# RZN2H register map
Vendor: Renesas Electronics Corporation; Series: RZN; File version: 1.00.00
CPU: other r0p0, little endian, MPU, no FPU, VTOR, 4 interrupt priority bits, 624 interrupts
Registers are 32-bit, read-write, reset 0x0 unless marked. A register's access mark holds for its fields unless they carry their own. Offsets are from the block's base; [hi:lo] are bit positions; {n}, {i} and the like mark numbered series; 'fields as' and 'values as' point back to an identical list.

## ENCSS — Encoder Interface Subsystem
Base 0x80291000
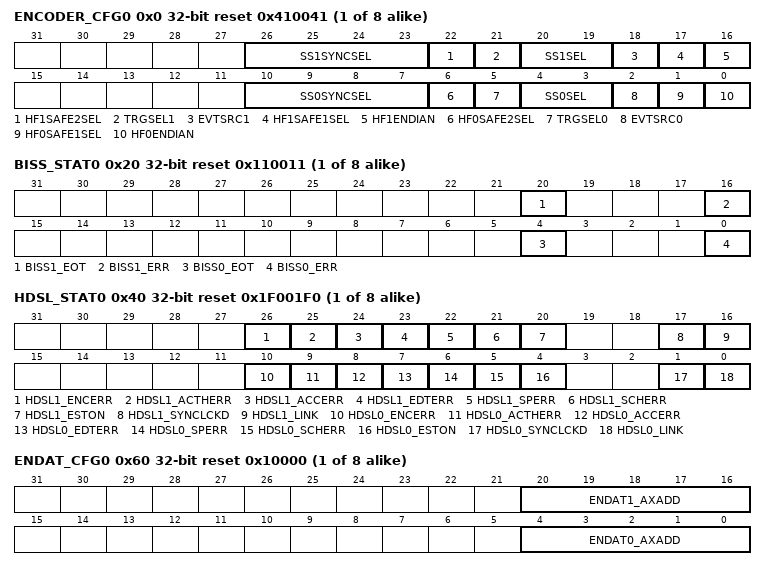
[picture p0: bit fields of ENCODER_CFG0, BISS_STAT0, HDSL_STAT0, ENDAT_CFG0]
{0x0+4i} ENCODER_CFG{i} (i=0..7) reset 0x410041 — Encoder IF Configuration Register {i}
  [26:23] SS1SYNCSEL — Event Source Unit Number Select
  [22] HF1SAFE2SEL — HIPERFACE DSL Unit 2*n+1 Safe 2 Interface Select
    0=Internal bus interface; 1=SPI interface
  [21] TRGSEL1 — EnDat 2.2 Unit 2*n+1 Trigger Output Source Select
    0=Synchronized Trigger out 2*n+1 from ELC; 1=Timer output from EnDat 2.2 Unit 2*n+1
  [20:19] SS1SEL — Encoder Interface Port Select
    0=HIPERFACE DSL; 1=BiSS-C; 2=EnDat 2.2; 3=A-format
  [18] EVTSRC1 — Event Source Select
    0=Trigger out 2*n+1 from ELC; 1=Trigger out from other units of encoder interface subsystem. Used unit is selected by SS0SYNCSEL[3:0] bits. The event source unit and triggered unit should be same protocol.
  [17] HF1SAFE1SEL — HIPERFACE DSL Unit 2*n+1 Safe 1 Interface Select
    0=Internal bus interface; 1=SPI interface
  [16] HF1ENDIAN — HIPERFACE DSL Unit 2*n+1 Endian Mode
    0=Little endian; 1=Big endian
  [10:7] SS0SYNCSEL — Event Source Unit Number Select
  [6] HF0SAFE2SEL — HIPERFACE DSL Unit 2*n Safe 2 Interface Select
    0=Internal bus interface; 1=SPI interface
  [5] TRGSEL0 — EnDat 2.2 Unit 2*n Trigger Output Source Select
    0=Synchronized Trigger out 2*n from ELC; 1=Timer output from EnDat 2.2 Unit 2*n
  [4:3] SS0SEL — Encoder Interface Port Select
    0=HIPERFACE DSL; 1=BiSS-C; 2=EnDat 2.2; 3=A-format
  [2] EVTSRC0 — Event Source Select
    0=Trigger out 2*n from ELC; 1=Trigger out from other units of encoder interface subsystem. Used unit is selected by SS0SYNCSEL[3:0] bits. The event source unit and triggered unit should be same protocol.
  [1] HF0SAFE1SEL — HIPERFACE DSL Unit 2*n Safe 1 Interface Select
    0=Internal bus interface; 1=SPI interface
  [0] HF0ENDIAN — HIPERFACE DSL Unit 2*n Endian Mode
    0=Little endian; 1=Big endian
{0x20+4i} BISS_STAT{i} (i=0..7) ro reset 0x110011 — BiSS-C Status Register {i}
  [20] BISS1_EOT — End-of-Transmission from BiSS-C Unit 2*n+1
    0=Data transmission active; 1=Data transmission inactive
  [16] BISS1_ERR — BiSS-C Unit 2*n+1 Error
    0=External or internal error occurred; 1=No error occurred
  [4] BISS0_EOT — End-of-Transmission from BiSS-C Unit 2*n
    0=Data transmission active; 1=Data transmission inactive
  [0] BISS0_ERR — BiSS-C Unit 2*n Error
    0=External or internal error occurred; 1=No error occurred
{0x40+4i} HDSL_STAT{i} (i=0..7) ro reset 0x1F001F0 — HIPERFACE DSL Status Register {i}
  [26] HDSL1_ENCERR — HIPERFACE-DSL Encoding Error
    0=No error; 1=Error
  [25] HDSL1_ACTHERR — HIPERFACE-DSL Acceleration Threshold Error
    0=No error; 1=Error
  [24] HDSL1_ACCERR — HIPERFACE-DSL Acceleration Error
    0=No error; 1=Error
  [23] HDSL1_EDTERR — HIPERFACE-DSL Estimator Deviation Threshold Error
    0=No error; 1=Error
  [22] HDSL1_SPERR — HIPERFACE-DSL Safe Position Error
    0=No error; 1=Error
  [21] HDSL1_SCHERR — HIPERFACE-DSL Safe Channel Error
    0=No error; 1=Error
  [20] HDSL1_ESTON — HIPERFACE-DSL Estimator ON
    0=Inactive; 1=Active
  [17] HDSL1_SYNCLCKD — HIPERFACE-DSL Sync Locked
    0=Unlock; 1=Locked
  [16] HDSL1_LINK — HIPERFACE-DSL Link
    0=Disconnect; 1=Connect
  [10] HDSL0_ENCERR — HIPERFACE-DSL Encoding Error
    0=No error; 1=Error
  [9] HDSL0_ACTHERR — HIPERFACE-DSL Acceleration Threshold Error
    0=No error; 1=Error
  [8] HDSL0_ACCERR — HIPERFACE-DSL Acceleration Error
    0=No error; 1=Error
  [7] HDSL0_EDTERR — HIPERFACE-DSL Estimator Deviation Threshold Error
    0=No error; 1=Error
  [6] HDSL0_SPERR — HIPERFACE-DSL Safe Position Error
    0=No error; 1=Error
  [5] HDSL0_SCHERR — HIPERFACE-DSL Safe Channel Error
    0=No error; 1=Error
  [4] HDSL0_ESTON — HIPERFACE-DSL Estimator ON
    0=Inactive; 1=Active
  [1] HDSL0_SYNCLCKD — HIPERFACE-DSL Sync Locked
    0=Unlock; 1=Locked
  [0] HDSL0_LINK — HIPERFACE-DSL Link
    0=Disconnect; 1=Connect
{0x60+4i} ENDAT_CFG{i} (i=0..7) reset 0x10000 — EnDat Configuration Register {i}
  [20:16] ENDAT1_AXADD — EnDat Unit 2*n+1 Axis Address
  [4:0] ENDAT0_AXADD — EnDat Unit 2*n Axis Address
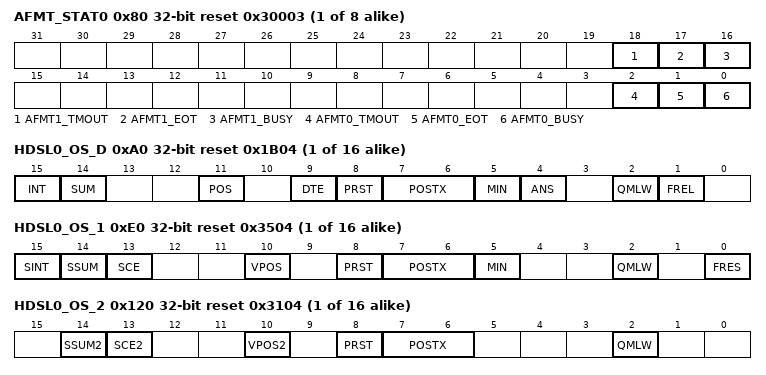
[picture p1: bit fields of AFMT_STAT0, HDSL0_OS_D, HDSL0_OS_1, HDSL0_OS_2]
{0x80+4i} AFMT_STAT{i} (i=0..7) ro reset 0x30003 — A-Format Status Register {i}
  [18] AFMT1_TMOUT — A-format Timeout
    0=No error; 1=Time out error
  [17] AFMT1_EOT — A-format End-of-Frame
    0=Data transfer end (cleared by data read); 1=Idle or in-progress
  [16] AFMT1_BUSY — A-format Busy
    0=Busy; 1=Idle
  [2] AFMT0_TMOUT — A-format Timeout
    0=No error; 1=Time out error
  [1] AFMT0_EOT — A-format End-Of-Frame
    values as AFMT1_EOT
  [0] AFMT0_BUSY — A-format Busy
    0=Busy; 1=Idle
{0xA0+4i} HDSL{i}_OS_D (i=0..15) ro reset 0x1B04 — HIPERFACE_DSL Online Status D Register {i}
  [15] INT — Status of the Interrupt Output
    0=Interrupt output on the low level; 1=Interrupt output on the high level
  [14] SUM — Summary Byte
    0=The last valid value from MIR_SUM was zero; 1=The last valid value from MIR_SUM was not zero. The importance of this flag depends on the particular error source that leads to a set MIR_SUM.
  [11] POS — Estimator Turned On
    0=No fast position error; 1=A source of an error in the fast position was identified or an alignment procedure is currently being carried out. It is probable that the last fast position is invalid. Be aware that the fast position read through drive interface is provided by the estimator.
  [9] DTE — Deviation Threshold Error
    0=Current value of deviation smaller than the specified maximum; 1=Current value of deviation greater than the specified maximum
  [8] PRST — Protocol Reset
    0=HDSLn running; 1=HDSLn has restarted the protocol
  [7:6] POSTX — Position Transmission Status
    0=Position request is transmitted to the DSL encoder; 1=Safe position 1 was received; 2=Fast position was received or position newly updated by estimator; 3=Safe position 2 was received
  [5] MIN — Acknowledgment of Message Initialization
    0=Parameter Channel not functioning; 1=The DSL encoder sends a figure by which the initialization of the Parameter Channel is acknowledged
  [4] ANS — Incorrect Answer Detected
    0=No error detected in the last answer to a long message; 1=The last answer to a long message was damaged
  [2] QMLW — Quality monitoring at Low level
    0=Current value of quality monitoring greater than or equal to 14; 1=Current value of quality monitoring less than 14
  [1] FREL — Channel Status for long message
    0=The channel for the long message is in use; 1=The channel for the long message is free
{0xE0+4i} HDSL{i}_OS_1 (i=0..15) ro reset 0x3504 — HIPERFACE_DSL Online Status 1 Register {i}
  [15] SINT — Status of the Interrupt Output
    values as HDSL0_OS_D.INT
  [14] SSUM — Safe Summary Bit
    0=The last valid value from SAFE_SUM was zero; 1=The last valid value from SAFE_SUM was not zero. The importance of this flag depends on the particular error source that leads to a set SAFE_SUM.
  [13] SCE — CRC Error on the Safe Channel
    0=The last Safe Channel CRC received was correct; 1=The last Safe Channel CRC received was wrong. It is expected that the last safe position 2 transmitted is invalid.
  [10] VPOS — Safe Position Invalid
    0=The last safe position received was correct; 1=An error in the safe position was identified. It is expected that the safe position transmitted from the encoder is invalid.
  [8] PRST — Protocol Reset
    0=HDSL0 running; 1=HDSL0 has restarted the protocol
  [7:6] POSTX — Position Transmission Status
    values as HDSL0_OS_D.POSTX
  [5] MIN — Acknowledgment of Message Initialization
    0=Parameter channel not functioning; 1=The DSL encoder sends a figure by which the initialization of the parameter channel is acknowledged
  [2] QMLW — Quality Monitoring at Low level
    values as HDSL0_OS_D.QMLW
  [0] FRES — Channel Status for the short message
    0=The channel for the short message is in use; 1=The channel for the short message is free
{0x120+4i} HDSL{i}_OS_2 (i=0..15) ro reset 0x3104 — HIPERFACE_DSL Online Status 2 Register {i}
  [14] SSUM2 — Summary Bit Channel 2
    0=Neither TEST2 nor ERR2 is set; 1=One of the indications TEST2 or ERR2 is set. The error reaction to the flag depends on the meaning of the bit.
  [13] SCE2 — Transmission Error Channel 2
    0=The last data received in channel 2 was correct; 1=The last safe channel 2 CRC received was wrong. It is expected that the last safe position 2 transmitted is invalid. Suitable measures must be installed in the user application.
  [10] VPOS2 — Safe Position 2 Invalid
    0=The last safe position received in channel 2 was correct; 1=A source of an error in the safe position in channel 2 was identified. It is probable that the safe position transmitted from Channel 2 is invalid. Suitable measures must be installed in the user application.
  [8] PRST — Protocol Reset
    0=HDSL0 running; 1=HDSL0 has restarted the protocol
  [7:6] POSTX — Position Transmission Status
    values as HDSL0_OS_D.POSTX
  [2] QMLW — Quality Monitoring at Low level
    values as HDSL0_OS_D.QMLW
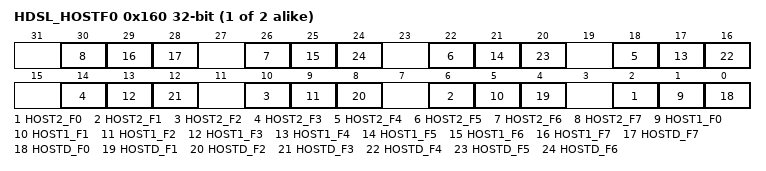
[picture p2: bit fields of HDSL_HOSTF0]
{0x160+4i} HDSL_HOSTF{i} (i=0..1) — HIPERFACE DSL Host_f Control Register {i}
  [all] fields
    0=Not freeze register update; 1=Freeze register update
  [4n+2] HOST2_F{n} (n=0..7)
  [4n+1] HOST1_F{n} (n=0..7)
  [28] HOSTD_F7 — Drive Interface Register Freeze (hostd_f) for HDSL Unit 8*n+7
  [4n] HOSTD_F{n} (n=0..6)
